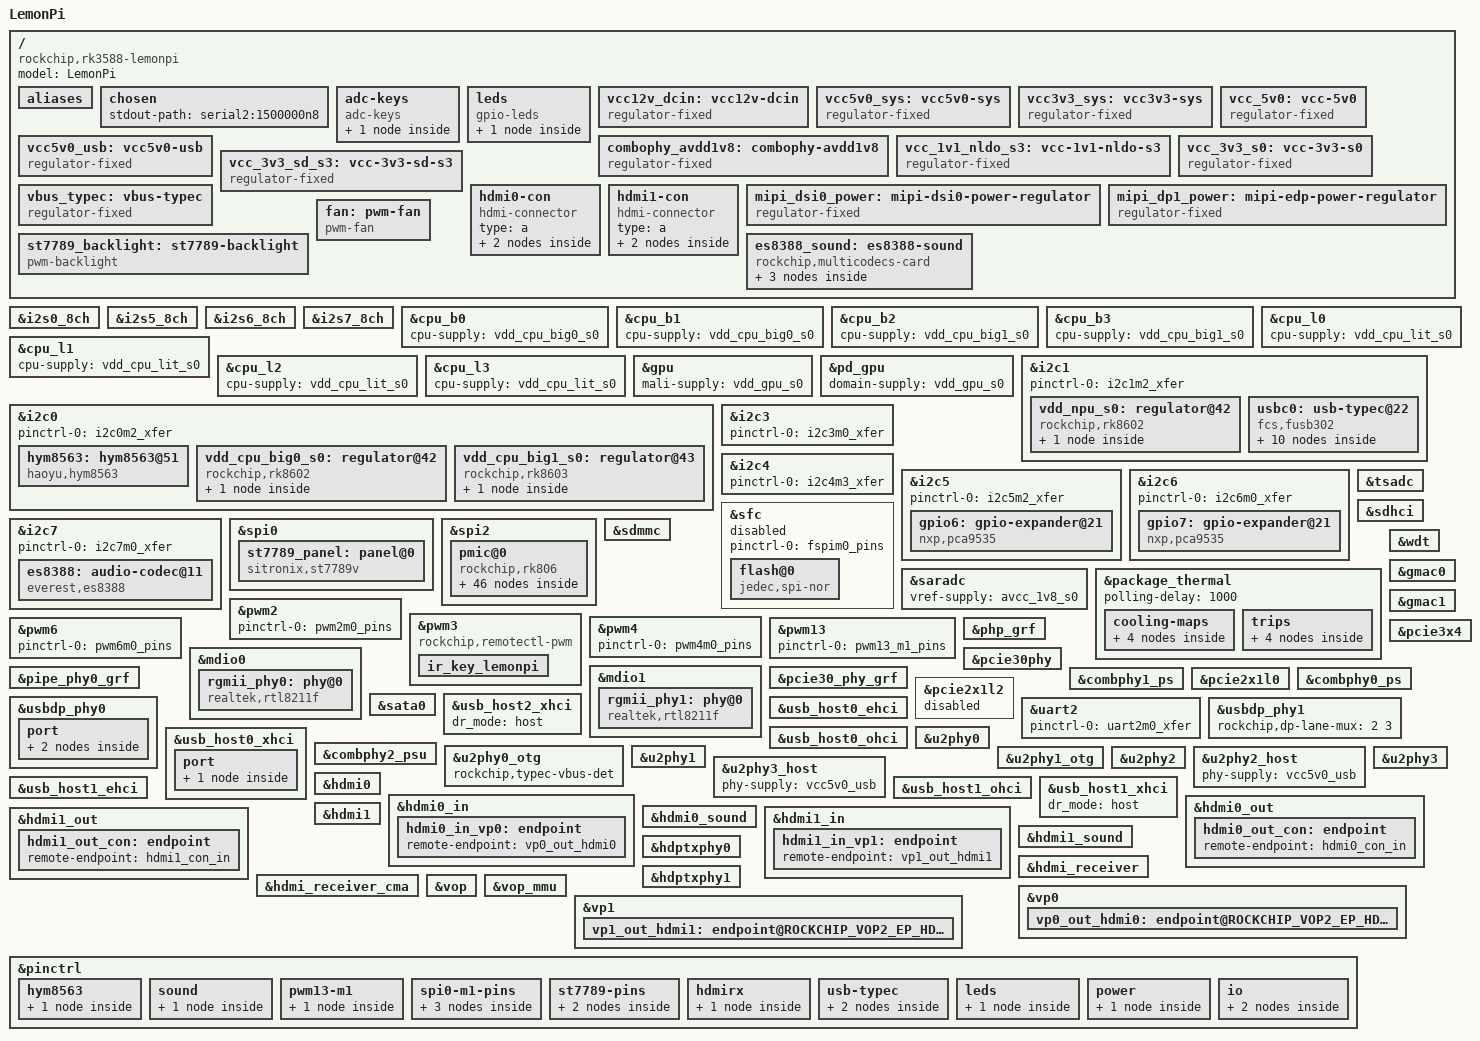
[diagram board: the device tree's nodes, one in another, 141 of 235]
// SPDX-License-Identifier: (GPL-2.0+ OR MIT)
/*
 * Copyright (c) 2021 Rockchip Electronics Co., Ltd.
 * Device Tree Source for LemonPi board on Rockchip RK3588 SoC.
 *
 */

/dts-v1/;
#include <dt-bindings/gpio/gpio.h>
#include <dt-bindings/input/input.h>
#include <dt-bindings/pinctrl/rockchip.h>
#include <dt-bindings/soc/rockchip,vop2.h>
#include <dt-bindings/usb/pd.h>
#include "rk3588.dtsi"

/ {
	model = "LemonPi";
	compatible = "rockchip,rk3588-lemonpi", "rockchip,rk3588";

	/* Device aliases for system devices */
	aliases {
		mmc0 = &sdhci;
		mmc1 = &sdmmc;
		ethernet0 = &gmac0;
		ethernet1 = &gmac1;
	};

	/* Kernel boot console output configuration */
	chosen {
		stdout-path = "serial2:1500000n8";
	};

	/* ADC keys for user buttons */
	adc-keys {
		compatible = "adc-keys";
		io-channels = <&saradc 1>;
		io-channel-names = "buttons";
		keyup-threshold-microvolt = <1800000>;
		poll-interval = <100>;
		status = "okay"; 
		
		power {
			label = "power";
			linux,code = <KEY_POWER>;
			press-threshold-microvolt = <1750>;
		};
	};

	/* On-board status LEDs */
	leds: leds {
		status = "okay";
		compatible = "gpio-leds";

		sys_led: sys-led {
			label = "sys_led";
			linux,default-trigger = "heartbeat";
			default-state = "on";
			gpios = <&gpio0 RK_PD3 GPIO_ACTIVE_LOW>;
			pinctrl-names = "default";
			pinctrl-0 = <&sys_led_pins>;
		};
	};

	/* 12V DC input power supply */
	vcc12v_dcin: vcc12v-dcin {
		compatible = "regulator-fixed";
		regulator-always-on;
		regulator-boot-on;
		regulator-min-microvolt = <12000000>;
		regulator-max-microvolt = <12000000>;
		regulator-name = "vcc12v_dcin";
	};

	/* 5V system power supply */
	vcc5v0_sys: vcc5v0-sys {
		compatible = "regulator-fixed";
		regulator-name = "vcc5v0_sys";
		regulator-always-on;
		regulator-boot-on;
		regulator-min-microvolt = <5000000>;
		regulator-max-microvolt = <5000000>;
		vin-supply = <&vcc12v_dcin>;
	};

	/* 3.3V system power supply */
	vcc3v3_sys: vcc3v3-sys {
		compatible = "regulator-fixed";
		regulator-name = "vcc3v3_sys";
		regulator-always-on;
		regulator-boot-on;
		regulator-min-microvolt = <3300000>;
		regulator-max-microvolt = <3300000>;
		vin-supply = <&vcc12v_dcin>;
	};

	/* 5V peripheral power supply */
	vcc_5v0: vcc-5v0 {
		compatible = "regulator-fixed";
		regulator-name = "vcc_5v0";
		regulator-always-on;
		regulator-boot-on;
		regulator-min-microvolt = <5000000>;
		regulator-max-microvolt = <5000000>;
		vin-supply = <&vcc5v0_sys>;
		enable-active-high;
		gpio = <&gpio4 RK_PA3 GPIO_ACTIVE_HIGH>;
		pinctrl-names = "default";
		pinctrl-0 = <&vcc_5v0_en>;
	};

	/* 5V USB power supply */
	vcc5v0_usb: vcc5v0-usb {
		compatible = "regulator-fixed";
		regulator-name = "vcc5v0_usb";
		regulator-always-on;
		regulator-boot-on;
		regulator-min-microvolt = <5000000>;
		regulator-max-microvolt = <5000000>;
		vin-supply = <&vcc5v0_sys>;
	};
	
	/* 1.8V Combo PHY analog power supply */
	combophy_avdd1v8: combophy-avdd1v8 {
		compatible = "regulator-fixed";
		regulator-name = "combophy_avdd1v8";
		regulator-boot-on;
		regulator-min-microvolt = <1800000>;
		regulator-max-microvolt = <1800000>;
		vin-supply = <&avcc_1v8_s0>;
	};

	/* 1.1V NLDO S3 power supply */
	vcc_1v1_nldo_s3: vcc-1v1-nldo-s3 {
		compatible = "regulator-fixed";
		regulator-name = "vcc_1v1_nldo_s3";
		regulator-always-on;
		regulator-boot-on;
		regulator-min-microvolt = <1100000>;
		regulator-max-microvolt = <1100000>;
		vin-supply = <&vcc5v0_sys>;
	};

	/* 3.3V S0 power supply */
	vcc_3v3_s0: vcc-3v3-s0 {
		compatible = "regulator-fixed";
		regulator-name = "vcc_3v3_s0";
		regulator-always-on;
		regulator-boot-on;
		regulator-min-microvolt = <3300000>;
		regulator-max-microvolt = <3300000>;
		vin-supply = <&vcc_3v3_s3>;
	};

	/* 3.3V SD S3 power supply */
	vcc_3v3_sd_s3: vcc-3v3-sd-s3 {
		compatible = "regulator-fixed";
		regulator-name = "vcc_3v3_sd_s3";
		regulator-always-on;
		regulator-boot-on;
		regulator-min-microvolt = <3300000>;
		regulator-max-microvolt = <3300000>;
		vin-supply = <&vcc_3v3_s3>;
	};

	/* Type-C VBUS power supply */
	vbus_typec: vbus-typec {
		compatible = "regulator-fixed";
		enable-active-high;
		gpio = <&gpio2 RK_PB5 GPIO_ACTIVE_HIGH>;
		pinctrl-names = "default";
		pinctrl-0 = <&typec_pwren>;
		regulator-name = "vbus_typec";
		regulator-min-microvolt = <5000000>;
		regulator-max-microvolt = <5000000>;
		regulator-always-on;
		regulator-boot-on;
		vin-supply = <&vcc5v0_usb>;
	};

	/* HDMI0 connector */
	hdmi0-con {
		compatible = "hdmi-connector";
		type = "a";

		port {
			hdmi0_con_in: endpoint {
				remote-endpoint = <&hdmi0_out_con>;
			};
		};
	};

	/* HDMI1 connector */
	hdmi1-con {
		compatible = "hdmi-connector";
		type = "a";
		port {
			hdmi1_con_in: endpoint {
				remote-endpoint = <&hdmi1_out_con>;
			};
		};
	};
	
	/* MIPI DSI0 power supply */
	mipi_dsi0_power: mipi-dsi0-power-regulator {
		compatible = "regulator-fixed";
		regulator-name = "mipi_dsi0_power";
		gpio = <&gpio1 RK_PD2 GPIO_ACTIVE_HIGH>;
		enable-active-high;
		regulator-boot-on;
		regulator-always-on;
	};

	/* MIPI eDP power supply */
	mipi_dp1_power: mipi-edp-power-regulator {
		compatible = "regulator-fixed";
		regulator-name = "mipi_dp1_power";
		gpio = <&gpio0 RK_PA0 GPIO_ACTIVE_HIGH>;
		enable-active-high;
		regulator-boot-on;
		regulator-always-on;
	};

	/* BEGIN: ST7789 Backlight Node */
	st7789_backlight: st7789-backlight { 
		compatible = "pwm-backlight";
		pwms = <&pwm13 0 100000 0>; 
		brightness-levels = <0 4 8 16 32 64 128 255>;
		default-brightness-level = <6>;
		power-supply = <&vcc3v3_sys>;
		status = "okay";
	};

	/* Audio codec and analog audio card (ES8388) */
	es8388_sound: es8388-sound {
		status = "okay";
		compatible = "rockchip,multicodecs-card";
		rockchip,card-name = "rockchip-es8388";
		hp-det-gpio = <&gpio1 RK_PD3 GPIO_ACTIVE_HIGH>;
		hp-con-gpio = <&gpio1 RK_PB5 GPIO_ACTIVE_HIGH>;
		io-channels = <&saradc 4>;
		io-channel-names = "adc-detect";
		keyup-threshold-microvolt = <1800000>;
		poll-interval = <100>;
		rockchip,format = "i2s";
		rockchip,mclk-fs = <256>;
		rockchip,cpu = <&i2s0_8ch>;
		rockchip,codec = <&es8388>;
		rockchip,audio-routing =
			"Headphone", "LOUT1",
			"Headphone", "ROUT1",
			"Headphone", "Headphone Power",
			"Headphone", "Headphone Power",
			"LINPUT1", "Main Mic",
			"LINPUT2", "Main Mic",
			"RINPUT1", "Headset Mic",
			"RINPUT2", "Headset Mic";
		pinctrl-names = "default";
		pinctrl-0 = <&hp_detect>;
		play-pause-key {
			label = "playpause";
			linux,code = <KEY_PLAYPAUSE>;
			press-threshold-microvolt = <2000>;
		};

		previous-song-key {
			label = "previoussong";
			linux,code = <KEY_PREVIOUSSONG>;
			press-threshold-microvolt = <145000>;
		};

		next-song-key {
			label = "nextsong";
			linux,code = <KEY_NEXTSONG>;
			press-threshold-microvolt = <290000>;
		};
	};

	/* PWM fan for system cooling */
	fan: pwm-fan {
		compatible = "pwm-fan";
		#cooling-cells = <2>;
		pwms = <&pwm4 0 50000 0>;
		cooling-levels = <0 25 100 150 255>;
	};
};

/* I2S0 8-channel audio interface */
&i2s0_8ch {
	status = "okay";
	rockchip,clk-trcm = <0>;
	pinctrl-names = "default"; 
	pinctrl-0 = <&i2s0_lrck
		     &i2s0_mclk
		     &i2s0_sclk
		     &i2s0_sdi0
		     &i2s0_sdo0>;
};

/* I2S5 8-channel audio interface */
&i2s5_8ch {
	status = "okay";
};

/* I2S6 8-channel audio interface */
&i2s6_8ch {
	status = "okay";
};

/* I2S7 8-channel audio interface */
&i2s7_8ch{
	status = "okay";
};

/* CPU big cluster 0 power supply */
&cpu_b0 {
	cpu-supply = <&vdd_cpu_big0_s0>;
};

/* CPU big cluster 1 power supply */
&cpu_b1 {
	cpu-supply = <&vdd_cpu_big0_s0>;
};

/* CPU big cluster 2 power supply */
&cpu_b2 {
	cpu-supply = <&vdd_cpu_big1_s0>;
};

/* CPU big cluster 3 power supply */
&cpu_b3 {
	cpu-supply = <&vdd_cpu_big1_s0>;
};

/* CPU little cluster 0 power supply */
&cpu_l0 {
	cpu-supply = <&vdd_cpu_lit_s0>;
};

/* CPU little cluster 1 power supply */
&cpu_l1 {
	cpu-supply = <&vdd_cpu_lit_s0>;
};

/* CPU little cluster 2 power supply */
&cpu_l2 {
	cpu-supply = <&vdd_cpu_lit_s0>;
};

/* CPU little cluster 3 power supply */
&cpu_l3 {
	cpu-supply = <&vdd_cpu_lit_s0>;
};

/* GPU configuration */
&gpu {
	mali-supply = <&vdd_gpu_s0>;
	status = "okay";
};

/* GPU power domain configuration */
&pd_gpu {
	domain-supply = <&vdd_gpu_s0>;
};

/* I2C0 bus for RTC and regulators */
&i2c0 {
	pinctrl-names = "default";
	pinctrl-0 = <&i2c0m2_xfer>;
	status = "okay";

	hym8563: hym8563@51 {
		compatible = "haoyu,hym8563";
		reg = <0x51>;
		#clock-cells = <0>;
		clock-frequency = <32768>;
		clock-output-names = "hym8563";
		pinctrl-names = "default";
		pinctrl-0 = <&hym8563_int>;
		interrupt-parent = <&gpio0>;
		interrupts = <RK_PB0 IRQ_TYPE_LEVEL_LOW>;
		wakeup-source;
	};

	vdd_cpu_big0_s0: regulator@42 {
		compatible = "rockchip,rk8602";
		reg = <0x42>;
		fcs,suspend-voltage-selector = <1>;
		regulator-compatible = "rk860x-reg";
		regulator-name = "vdd_cpu_big0_s0";
		regulator-always-on;
		regulator-boot-on;
		regulator-min-microvolt = <550000>;
		regulator-max-microvolt = <1050000>;
		regulator-ramp-delay = <2300>;
		vin-supply = <&vcc5v0_sys>;

		regulator-state-mem {
			regulator-off-in-suspend;
		};
	};

	vdd_cpu_big1_s0: regulator@43 {
		compatible = "rockchip,rk8603", "rockchip,rk8602";
		reg = <0x43>;
		fcs,suspend-voltage-selector = <1>;
		regulator-compatible = "rk860x-reg";
		regulator-name = "vdd_cpu_big1_s0";
		regulator-always-on;
		regulator-boot-on;
		regulator-min-microvolt = <550000>;
		regulator-max-microvolt = <1050000>;
		regulator-ramp-delay = <2300>;
		vin-supply = <&vcc5v0_sys>;

		regulator-state-mem {
			regulator-off-in-suspend;
		};
	};
};

/* I2C1 bus for NPU regulator and Type-C controller */
&i2c1 {
	pinctrl-names = "default";
	pinctrl-0 = <&i2c1m2_xfer>;
	status = "okay";

	vdd_npu_s0: regulator@42 {
		compatible = "rockchip,rk8602";
		reg = <0x42>;
		vin-supply = <&vcc5v0_sys>;
		regulator-compatible = "rk860x-reg";
		regulator-name = "vdd_npu_s0";
		regulator-min-microvolt = <550000>;
		regulator-max-microvolt = <950000>;
		regulator-ramp-delay = <2300>;
		rockchip,suspend-voltage-selector = <1>;
		regulator-boot-on;
		regulator-always-on;

		regulator-state-mem {
			regulator-off-in-suspend;
		};
	};

	usbc0: usb-typec@22 {
		compatible = "fcs,fusb302";
		reg = <0x22>;
		interrupt-parent = <&gpio0>;
		interrupts = <RK_PC4 IRQ_TYPE_LEVEL_LOW>;
		pinctrl-names = "default";
		pinctrl-0 = <&usbc0_int>;
		vbus-supply = <&vbus_typec>;
		status = "okay";

		usb_con: connector {
			compatible = "usb-c-connector";
			label = "USB-C";
			data-role = "dual";
			power-role = "dual";
			try-power-role = "sink";
			op-sink-microwatt = <1000000>;
			sink-pdos = <PDO_FIXED(5000, 1000, PDO_FIXED_USB_COMM)>;
			source-pdos = <PDO_FIXED(5000, 3000, PDO_FIXED_USB_COMM)>;

			altmodes {
				#address-cells = <1>;
				#size-cells = <0>;

				altmode@0 {
					reg = <0>;
					svid = <0xff01>;
					vdo = <0xffffffff>;
				};
			};

			ports {
				#address-cells = <1>;
				#size-cells = <0>;

				port@0 {
					reg = <0>;
					usbc0_orien_sw: endpoint {
						remote-endpoint = <&usbdp_phy0_orientation_switch>;
					};
				};

				port@1 {
					reg = <1>;

					usbc0_role_sw: endpoint {
						remote-endpoint = <&dwc3_0_role_switch>;
					};
				};

				port@2 {
					reg = <2>;

					dp_altmode_mux: endpoint {
						remote-endpoint = <&usbdp_phy0_dp_altmode_mux>;
					};
				};
			};
		};
	};
};

/* I2C3 bus */
&i2c3 {
	status = "okay";
	pinctrl-names = "default";
	pinctrl-0 = <&i2c3m0_xfer>;
};

/* I2C4 bus */
&i2c4 {
	status = "okay";
	pinctrl-names = "default";
	pinctrl-0 = <&i2c4m3_xfer>;
};

/* I2C5 bus with GPIO expander */
&i2c5 {
	pinctrl-names = "default";
	pinctrl-0 = <&i2c5m2_xfer>;
	status = "okay";

	gpio6: gpio-expander@21 {
		compatible = "nxp,pca9535";
		vcc-supply = <&vcc_3v3_s0>;
		status = "okay";
		reg = <0x21>;
		gpio-controller;
		#gpio-cells = <2>;
	};
};

/* I2C6 bus with GPIO expander */
&i2c6 {
	status = "okay";
	pinctrl-names = "default";
	pinctrl-0 = <&i2c6m0_xfer>;

	gpio7: gpio-expander@21 {
		compatible = "nxp,pca9535";
		status = "okay";
		reg = <0x21>;
		gpio-controller;
		#gpio-cells = <2>;
	};
};

/* I2C7 bus for ES8388 Audio Codec */
&i2c7 { 
	pinctrl-names = "default";
	pinctrl-0 = <&i2c7m0_xfer>;
	status = "okay";

	es8388: audio-codec@11 {
		status = "okay";
		#sound-dai-cells = <0>;
		compatible = "everest,es8388", "everest,es8323";
		reg = <0x11>;
		clocks = <&cru I2S0_8CH_MCLKOUT>;
		clock-names = "mclk";
		assigned-clocks = <&cru I2S0_8CH_MCLKOUT>;
		assigned-clock-rates = <12288000>;
		/* 从 ES8388 节点中移除 MCLK 的 pinctrl 声明 */
		// pinctrl-names = "default";
		// pinctrl-0 = <&i2s0_mclk>;
		DVDD-supply = <&vcc_1v8_s0>;
		AVDD-supply = <&avcc_1v8_s0>;
		PVDD-supply = <&vcc_3v3_s0>;
		HPVDD-supply = <&vcc_3v3_s0>;
	};
};

&sfc {
	status = "disabled"; 
	pinctrl-names = "default";
	pinctrl-0 = <&fspim0_pins>;

	flash@0 {
		compatible = "jedec,spi-nor";
		reg = <0x0>;
		spi-max-frequency = <100000000>;
		spi-rx-bus-width = <4>; 
		spi-tx-bus-width = <1>;
	};
};

/* SPI0 bus for pwm13 */
&spi0 {
	pinctrl-names = "default";
	pinctrl-0 = <&spi0m1_clk_pins>, <&spi0m1_mosi_pins>,
				<&spi0m1_cs0_pins>;
	status = "okay";

	st7789_panel: panel@0 {
		compatible = "sitronix,st7789v";
		reg = <0>;
        spi-max-frequency = <48000000>;
		/* For SPI Mode 0 (CPOL=0, CPHA=0), no spi-cpol or spi-cpha flags needed */

		/*
		 * The pinctrl for DC and RESET pins (configured as GPIOs) is handled
		 * by the pinctrl definitions under &pinctrl { st7789_gpio_pins { ... } }.
		 * The panel driver will request these GPIOs using the dc-gpios and reset-gpios
		 * properties. The panel node itself typically does not need its own pinctrl-0
		 * if these are standard GPIO controls.
		 * So, the following line should be removed:
		 * pinctrl-names = "default";
		 * pinctrl-0 = <&st7789_dc_pins>, <&st7789_reset_pins>;
		 */

		pinctrl-names = "default";
		pinctrl-0 = <&st7789_dc_pins>, <&st7789_reset_pins>;
		reset-gpios = <&gpio4 RK_PB0 GPIO_ACTIVE_LOW>;
		dc-gpios = <&gpio4 RK_PA0 GPIO_ACTIVE_HIGH>;

		backlight = <&st7789_backlight>;

		width = <172>;
		height = <320>;
		rotate = <90>;
		fps = <30>;
		buswidth = <8>;
		status = "okay";
	};
};

/* SPI2 bus for PMIC */
&spi2 {
	status = "okay";
	assigned-clocks = <&cru CLK_SPI2>;
	assigned-clock-rates = <200000000>;
	pinctrl-names = "default";
	pinctrl-0 = <&spi2m2_cs0 &spi2m2_pins>;
	num-cs = <1>;

	pmic@0 {
		compatible = "rockchip,rk806";
		spi-max-frequency = <1000000>;
		reg = <0x0>;

		interrupt-parent = <&gpio0>;
		interrupts = <7 IRQ_TYPE_LEVEL_LOW>;

		pinctrl-names = "default";
		pinctrl-0 = <&pmic_pins>, <&rk806_dvs1_null>,
				<&rk806_dvs2_null>, <&rk806_dvs3_null>;
		system-power-controller;

		vcc1-supply = <&vcc5v0_sys>;
		vcc2-supply = <&vcc5v0_sys>;
		vcc3-supply = <&vcc5v0_sys>;
		vcc4-supply = <&vcc5v0_sys>;
		vcc5-supply = <&vcc5v0_sys>;
		vcc6-supply = <&vcc5v0_sys>;
		vcc7-supply = <&vcc5v0_sys>;
		vcc8-supply = <&vcc5v0_sys>;
		vcc9-supply = <&vcc5v0_sys>;
		vcc10-supply = <&vcc5v0_sys>;
		vcc11-supply = <&vcc_2v0_pldo_s3>;
		vcc12-supply = <&vcc5v0_sys>;
		vcc13-supply = <&vcc_1v1_nldo_s3>;
		vcc14-supply = <&vcc_1v1_nldo_s3>;
		vcca-supply = <&vcc5v0_sys>;

		gpio-controller;
		#gpio-cells = <2>;

		rk806_dvs1_null: dvs1-null-pins {
			pins = "gpio_pwrctrl1";
			function = "pin_fun0";
		};

		rk806_dvs2_null: dvs2-null-pins {
			pins = "gpio_pwrctrl2";
			function = "pin_fun0";
		};

		rk806_dvs3_null: dvs3-null-pins {
			pins = "gpio_pwrctrl3";
			function = "pin_fun0";
		};

		regulators {
			vdd_gpu_s0: dcdc-reg1 {
				regulator-always-on;
				regulator-boot-on;
				regulator-min-microvolt = <550000>;
				regulator-max-microvolt = <950000>;
				regulator-ramp-delay = <12500>;
				regulator-name = "vdd_gpu_s0";
				regulator-enable-ramp-delay = <400>;
				
				regulator-state-mem {
					regulator-off-in-suspend;
				};
			};

			vdd_cpu_lit_s0: dcdc-reg2 {
				regulator-name = "vdd_cpu_lit_s0";
				regulator-always-on;
				regulator-boot-on;
				regulator-min-microvolt = <550000>;
				regulator-max-microvolt = <950000>;
				regulator-ramp-delay = <12500>;

				regulator-state-mem {
					regulator-off-in-suspend;
				};
			};

			vdd_log_s0: dcdc-reg3 {
				regulator-always-on;
				regulator-boot-on;
				regulator-min-microvolt = <675000>;
				regulator-max-microvolt = <750000>;
				regulator-ramp-delay = <12500>;
				regulator-name = "vdd_log_s0";

				regulator-state-mem {
					regulator-off-in-suspend;
					regulator-suspend-microvolt = <750000>;
				};
			};

			vdd_vdenc_s0: dcdc-reg4 {
				regulator-name = "vdd_vdenc_s0";
				regulator-always-on;
				regulator-boot-on;
				regulator-min-microvolt = <550000>;
				regulator-max-microvolt = <950000>;
				regulator-init-microvolt = <750000>;
				regulator-ramp-delay = <12500>;

				regulator-state-mem {
					regulator-off-in-suspend;
				};
			};

			vdd_ddr_s0: dcdc-reg5 {
				regulator-name = "vdd_ddr_s0";
				regulator-always-on;
				regulator-boot-on;
				regulator-min-microvolt = <675000>;
				regulator-max-microvolt = <900000>;
				regulator-ramp-delay = <12500>;

				regulator-state-mem {
					regulator-off-in-suspend;
					regulator-suspend-microvolt = <850000>;
				};
			};

			vdd2_ddr_s3: dcdc-reg6 {
				regulator-always-on;
				regulator-boot-on;
				regulator-name = "vdd2_ddr_s3";
				
				regulator-state-mem {
					regulator-on-in-suspend;
				};
			};

			vcc_2v0_pldo_s3: dcdc-reg7 {
				regulator-always-on;
				regulator-boot-on;
				regulator-min-microvolt = <2000000>;
				regulator-max-microvolt = <2000000>;
				regulator-ramp-delay = <12500>;
				regulator-name = "vdd_2v0_pldo_s3";

				regulator-state-mem {
					regulator-on-in-suspend;
					regulator-suspend-microvolt = <2000000>;
				};
			};

			vcc_3v3_s3: dcdc-reg8 {
				regulator-always-on;
				regulator-boot-on;
				regulator-min-microvolt = <3300000>;
				regulator-max-microvolt = <3300000>;
				regulator-name = "vcc_3v3_s3";

				regulator-state-mem {
					regulator-on-in-suspend;
					regulator-suspend-microvolt = <3300000>;
				};
			};

			vddq_ddr_s0: dcdc-reg9 {
				regulator-always-on;
				regulator-boot-on;
				regulator-name = "vddq_ddr_s0";

				regulator-state-mem {
					regulator-off-in-suspend;
				};
			};

			vcc_1v8_s3: dcdc-reg10 {
				regulator-always-on;
				regulator-boot-on;
				regulator-min-microvolt = <1800000>;
				regulator-max-microvolt = <1800000>;
				regulator-name = "vcc_1v8_s3";

				regulator-state-mem {
					regulator-on-in-suspend;
					regulator-suspend-microvolt = <1800000>;
				};
			};

			avcc_1v8_s0: pldo-reg1 {
				regulator-always-on;
				regulator-boot-on;
				regulator-min-microvolt = <1800000>;
				regulator-max-microvolt = <1800000>;
				regulator-name = "avcc_1v8_s0";

				regulator-state-mem {
					regulator-off-in-suspend;
				};
			};

			vcc_1v8_s0: pldo-reg2 {
				regulator-always-on;
				regulator-boot-on;
				regulator-min-microvolt = <1800000>;
				regulator-max-microvolt = <1800000>;
				regulator-name = "vcc_1v8_s0";

				regulator-state-mem {
					regulator-off-in-suspend;
					regulator-suspend-microvolt = <1800000>;
				};
			};

			avdd_1v2_s0: pldo-reg3 {
				regulator-always-on;
				regulator-boot-on;
				regulator-min-microvolt = <1200000>;
				regulator-max-microvolt = <1200000>;
				regulator-name = "avdd_1v2_s0";

				regulator-state-mem {
					regulator-off-in-suspend;
				};
			};

			avcc_3v3_s0: pldo-reg4 {
				regulator-always-on;
				regulator-boot-on;
				regulator-min-microvolt = <3300000>;
				regulator-max-microvolt = <3300000>;
				regulator-name = "avcc_3v3_s0";
				
				regulator-state-mem {
					regulator-off-in-suspend;
				};
			};

			vccio_sd_s0: pldo-reg5 {
				regulator-always-on;
				regulator-boot-on;
				regulator-min-microvolt = <1800000>;
				regulator-max-microvolt = <3300000>;
				regulator-ramp-delay = <12500>;
				regulator-name = "vccio_sd_s0";

				regulator-state-mem {
					regulator-off-in-suspend;
				};
			};

			pldo6_s3: pldo-reg6 {
				regulator-always-on;
				regulator-boot-on;
				regulator-min-microvolt = <1800000>;
				regulator-max-microvolt = <1800000>;
				regulator-name = "pldo6_s3";

				regulator-state-mem {
					regulator-on-in-suspend;
					regulator-suspend-microvolt = <1800000>;
				};
			};

			vdd_0v75_s3: nldo-reg1 {
				regulator-always-on;
				regulator-boot-on;
				regulator-min-microvolt = <750000>;
				regulator-max-microvolt = <750000>;
				regulator-name = "vdd_0v75_s3";

				regulator-state-mem {
					regulator-on-in-suspend;
					regulator-suspend-microvolt = <750000>;
				};
			};

			vdd_ddr_pll_s0: nldo-reg2 {
				regulator-always-on;
				regulator-boot-on;
				regulator-min-microvolt = <850000>;
				regulator-max-microvolt = <850000>;
				regulator-name = "vdd_ddr_pll_s0";

				regulator-state-mem {
					regulator-off-in-suspend;
					regulator-suspend-microvolt = <850000>;
				};
			};

			avdd_0v75_s0: nldo-reg3 {
				regulator-always-on;
				regulator-boot-on;
				regulator-min-microvolt = <750000>;
				regulator-max-microvolt = <750000>;
				regulator-name = "avdd_0v75_s0";

				regulator-state-mem {
					regulator-off-in-suspend;
				};
			};

			vdd_0v85_s0: nldo-reg4 {
				regulator-always-on;
				regulator-boot-on;
				regulator-min-microvolt = <850000>;
				regulator-max-microvolt = <850000>;
				regulator-name = "vdd_0v85_s0";

				regulator-state-mem {
					regulator-off-in-suspend;
				};
			};

			vdd_0v75_s0: nldo-reg5 {
				regulator-always-on;
				regulator-boot-on;
				regulator-min-microvolt = <750000>;
				regulator-max-microvolt = <750000>;
				regulator-name = "vdd_0v75_s0";

				regulator-state-mem {
					regulator-off-in-suspend;
				};
			};
		};
	};
};

/* SARADC analog-to-digital converter */
&saradc {
	status = "okay";
	vref-supply = <&avcc_1v8_s0>;
};

/* TSADC thermal sensor */
&tsadc {
	status = "okay";
};

/* eMMC storage */
&sdhci {
	assigned-clock-rates = <200000000>, <24000000>, <200000000>;
	bus-width = <8>;
	max-frequency = <200000000>;
	mmc-hs200-1_8v;		
	non-removable;	
	pinctrl-names = "default";
	pinctrl-0 = <&emmc_bus8 &emmc_clk &emmc_cmd>;	
	supports-emmc;
	status = "okay";
};

/* microSD card slot */
&sdmmc {
	bus-width = <4>;
	cap-mmc-highspeed;
	cap-sd-highspeed;
	disable-wp;
	no-mmc;
	no-sdio;
	max-frequency = <50000000>;
	vmmc-supply = <&vcc_3v3_s3>;
	vqmmc-supply = <&vccio_sd_s0>;
	status = "okay";
};

/* Fan thermal zone and cooling maps */
&package_thermal {
	polling-delay = <1000>;

	cooling-maps {
		map0 {
			trip = <&package_fan0>;
			cooling-device = <&fan 1 1>;
		};

		map1 {
			trip = <&package_fan1>;
			cooling-device = <&fan 2 2>;
		};

		map3 {
			trip = <&package_fan2>;
			cooling-device = <&fan 3 3>;
		};

		map4 {
			trip = <&package_fan3>;
			cooling-device = <&fan 4 4>;
		};
	};

	trips {
		package_fan0: package-fan0 {
			temperature = <50000>;
			hysteresis = <5000>;
			type = "active";
		};

		package_fan1: package-fan1 {
			temperature = <55000>;
			hysteresis = <5000>;
			type = "active";
		};

		package_fan2: package-fan2 {
			temperature = <60000>;
			hysteresis = <5000>;
			type = "active";
		};

		package_fan3: package-fan3 {
			temperature = <65000>;
			hysteresis = <5000>;
			type = "active";
		};
	};
};

/* PWM2 controller */
&pwm2 {
	pinctrl-0 = <&pwm2m0_pins>;
	status = "okay";
};

/* PWM3 for IR receiver */
&pwm3 { 
	compatible = "rockchip,remotectl-pwm";
	pinctrl-names = "default";
	pinctrl-0 = <&pwm3m1_pins>;
	remote_pwm_id = <3>;
	handle_cpu_id = <1>;
	remote_support_psci = <0>;
	status = "okay";

	ir_key_lemonpi{
	rockchip,usercode = <0xff00>;
	rockchip,key_table =
		<0xba   KEY_POWER>,      /* 电源按键 */
		<0xb8   KEY_MENU>,       /* 菜单按键 */
		<0xbc   KEY_BACK>,       /* 返回按键 */
		<0xbb   KEY_HOME>,       /* home键按键 */
		<0xea   KEY_PLAY>,       /* 播放按键 */
		<0xbf   KEY_VOLUMEUP>,   /* 音量加按键 */
		<0xe6   KEY_VOLUMEDOWN>, /* 音量键按键 */
		<0xf6   KEY_FASTFORWARD>,/* 快进按键 */
		<0xf8   KEY_FASTREVERSE>,/* 快退按键 */
		<0xf2   KEY_BACKSPACE>,  /* BaskSpace按键 */
		<0xf3   KEY_1>,          /* 按键1 */
        <0xe7   KEY_2>,
        <0xa1   KEY_3>,
        <0xf7   KEY_4>,
        <0xe3   KEY_5>,
        <0xa5   KEY_6>,
        <0xbd   KEY_7>,
        <0xad   KEY_8>,
        <0xb5   KEY_9>,
		<0xe9   KEY_0>;          /* 按键0 */
	};
};

/* PWM4 controller */
&pwm4 {
	pinctrl-0 = <&pwm4m0_pins>;
	status = "okay";
};

/* PWM6 controller */
&pwm6 {
	pinctrl-0 = <&pwm6m0_pins>;
	status = "okay";
};

/* PWM13 controller */
&pwm13 {
    pinctrl-names = "default";
    pinctrl-0 = <&pwm13_m1_pins>; 
	status = "okay";
};

/* Watchdog timer */
&wdt {
	status = "okay";
};

/* GMAC0 Ethernet controller */
&gmac0 {
	/* Use rgmii-rxid mode to disable rx delay inside Soc */
	phy-mode = "rgmii-rxid";
	clock_in_out = "output";

	snps,reset-gpio = <&gpio4 RK_PC6 GPIO_ACTIVE_LOW>;
	snps,reset-active-low;
	/* Reset time is 20ms, 100ms for rtl8211f */
	snps,reset-delays-us = <0 20000 100000>;

	pinctrl-names = "default";
	pinctrl-0 = <&gmac0_miim
			 &gmac0_tx_bus2
			 &gmac0_rx_bus2
			 &gmac0_rgmii_clk
			 &gmac0_rgmii_bus>;

	tx_delay = <0x20>;
	/* rx_delay = <0x4f>; */

	phy-handle = <&rgmii_phy0>;
	status = "okay";
};

/* GMAC1 Ethernet controller */
&gmac1 {
	/* Use rgmii-rxid mode to disable rx delay inside Soc */
	phy-mode = "rgmii-rxid";
	clock_in_out = "output";

	snps,reset-gpio = <&gpio3 RK_PB7 GPIO_ACTIVE_LOW>;
	snps,reset-active-low;
	/* Reset time is 20ms, 100ms for rtl8211f */
	snps,reset-delays-us = <0 20000 100000>;

	pinctrl-names = "default";
	pinctrl-0 = <&gmac1_miim
			 &gmac1_tx_bus2
			 &gmac1_rx_bus2
			 &gmac1_rgmii_clk
			 &gmac1_rgmii_bus>;

	tx_delay = <0x20>;
	/* rx_delay = <0x4f>; */

	phy-handle = <&rgmii_phy1>;
	status = "okay";
};

/* MDIO0 bus for GMAC0 PHY */
&mdio0 {
	status = "okay";
	rgmii_phy0: phy@0 {
		compatible = "realtek,rtl8211f", "ethernet-phy-ieee802.3-c22";
		phy-supply = <&vcc3v3_sys>;
		reg = <0x00>;
	};
};

/* MDIO1 bus for GMAC1 PHY */
&mdio1 {
	status = "okay";
	rgmii_phy1: phy@0 {
		compatible = "realtek,rtl8211f", "ethernet-phy-ieee802.3-c22";
		phy-supply = <&vcc3v3_sys>;
		reg = <0x00>;
	};
};

&php_grf { 
    status = "okay";
};

&pipe_phy0_grf { 
    status = "okay";
};

/* PCIe3.0 PHY Port0 & Port1 */
&pcie30phy {
	status = "okay";
};

&pcie30_phy_grf {
	status = "okay";
};

/* PCIe3x4 M.2 M-Key slot */
&pcie3x4 {
	reset-gpios = <&gpio1 RK_PB2 GPIO_ACTIVE_HIGH>;
	vpcie3v3-supply = <&vcc3v3_sys>;
	num-lanes = <4>;
	status = "okay";
};

/* SATA30_HOST1/PCIe20x1_0 Combo PHY */
&combphy1_ps {
	status = "okay";
};

/* PCIe2x1l0 M.2 E-Key slot */
&pcie2x1l0 {
	reset-gpios = <&gpio4 RK_PA5 GPIO_ACTIVE_HIGH>;
	disable-gpios = <&gpio0 RK_PC6 GPIO_ACTIVE_HIGH>;
	status = "okay";
};

/* SATA30/PCIe20x1_2 Combo PHY */
&combphy0_ps {
	status = "okay";
};

/* PCIe2x1l2 slot */
&pcie2x1l2 {
	reset-gpios = <&gpio3 RK_PD1 GPIO_ACTIVE_HIGH>;
	disable-gpios = <&gpio3 RK_PC1 GPIO_ACTIVE_HIGH>;
	status = "disabled";
};

/* SATA-PCIe controller */
&sata0{
	ahci-supply = <&vcc_1v8_s0>;
	phy-supply = <&avcc_1v8_s0>; 
	status = "okay";
};

/* Debug UART2 */
&uart2 {
	pinctrl-0 = <&uart2m0_xfer>;
	status = "okay";
};

/* USB3 PHY for USB 3.0 Type-A port 1 */
&usbdp_phy1 {
	rockchip,dp-lane-mux = <2 3>;
	status = "okay";
};

/* USB 3.0 Type-A port 2 (lower) */
&usb_host2_xhci {
	status = "okay";
	dr_mode = "host";
};

/* USB3 PHY for USB Type-C port */
&usbdp_phy0 {
    orientation-switch;
    sbu1-dc-gpios = <&gpio1 RK_PA0 GPIO_ACTIVE_HIGH>;
    sbu2-dc-gpios = <&gpio1 RK_PA1 GPIO_ACTIVE_HIGH>;
    status = "okay";

    port {
        #address-cells = <1>;
        #size-cells = <0>;

		usbdp_phy0_orientation_switch: endpoint@0 {
            reg = <0>;
			remote-endpoint = <&usbc0_orien_sw>;
        };

		usbdp_phy0_dp_altmode_mux: endpoint@1 {
            reg = <1>;
			remote-endpoint = <&dp_altmode_mux>;
        };
    };
};

/* USB 2.0 Type-A port 0 */
&usb_host0_ehci {
	status = "okay";
};

/* USB 2.0 Type-A port 0 */
&usb_host0_ohci {
	status = "okay";
};

/* USB Type-C port 0 */
&usb_host0_xhci {
	dr_mode = "host";
	usb-role-switch;
	status = "okay";

	port {
		#address-cells = <1>;
		#size-cells = <0>;

		dwc3_0_role_switch: endpoint@0 {
			reg = <0>;
			remote-endpoint = <&usbc0_role_sw>;
		};
	};
};

/* Combo PHY 2 as USB3 PHY */
&combphy2_psu {
	status = "okay";
};

/* USB2 PHY for USB Type-C port */
&u2phy0 {
	status = "okay";
};

&u2phy0_otg {
	rockchip,typec-vbus-det;
	status = "okay";
};

/* USB2 PHY for USB 3.0 Type-A port 1 */
&u2phy1 {
	status = "okay";
};

&u2phy1_otg {
	status = "okay";
};

/* USB2 PHY for USB 2.0 Type-A port 2 */
&u2phy2 {
	status = "okay";
};

&u2phy2_host {
	phy-supply = <&vcc5v0_usb>;
	status = "okay";
};

/* USB2 PHY for USB 3.0 Type-A port 2 */
&u2phy3 {
	status = "okay";
};

&u2phy3_host {
	phy-supply = <&vcc5v0_usb>;
	status = "okay";
};

/* USB2.0 HOST1 Controller */
&usb_host1_ehci {
	status = "okay";
};

/* USB 3.0 Type-A port 2 (lower) */
&usb_host1_ohci {
	status = "okay";
};

/* USB 3.0 Type-A port 1 (upper) */
&usb_host1_xhci {
	dr_mode = "host";
	status = "okay";
};

/* HDMI0 controller */
&hdmi0 {
	status = "okay";
};

/* HDMI1 input endpoint */
&hdmi0_in {
	hdmi0_in_vp0: endpoint {
		remote-endpoint = <&vp0_out_hdmi0>;
	};
};

/* HDMI0 output endpoint */
&hdmi0_out {
	hdmi0_out_con: endpoint {
		remote-endpoint = <&hdmi0_con_in>;
	};
};

/* HDMI0 audio */
&hdmi0_sound {
	status = "okay";
};

/* HDMI1 controller */
&hdmi1 {
	status = "okay";
};

/* HDMI1 input endpoint */
&hdmi1_in {
	hdmi1_in_vp1: endpoint {
		remote-endpoint = <&vp1_out_hdmi1>;
	};
};

/* HDMI1 output endpoint */
&hdmi1_out {
	hdmi1_out_con: endpoint {
		remote-endpoint = <&hdmi1_con_in>;
	};
};

/* HDMI1 audio */
&hdmi1_sound {
	status = "okay";
};

/* HDMI receiver CMA memory */
&hdmi_receiver_cma {
	status = "okay";
};

/* HDMI receiver */
&hdmi_receiver {
	status = "okay";
	hpd-gpios = <&gpio1 RK_PD5 GPIO_ACTIVE_LOW>;
	pinctrl-0 = <&hdmim1_rx_cec &hdmim1_rx_hpdin &hdmim1_rx_scl &hdmim1_rx_sda &hdmirx_hpd>;
	pinctrl-names = "default";
	memory-region = <&hdmi_receiver_cma>;
};

/* HDMI PHY0 */
&hdptxphy0 {
	status = "okay";
};

/* HDMI PHY1 */
&hdptxphy1 {
	status = "okay";
};

/* Video Output Processor */
&vop {
	status = "okay";
};

/* VOP Memory Management Unit */
&vop_mmu {
	status = "okay";
};

/* VOP2 HDMI0 endpoint */
&vp0 {
	vp0_out_hdmi0: endpoint@ROCKCHIP_VOP2_EP_HDMI0 {
		reg = <ROCKCHIP_VOP2_EP_HDMI0>;
		remote-endpoint = <&hdmi0_in_vp0>;
	};
};

/* VOP2 HDMI1 endpoint */
&vp1 {
	vp1_out_hdmi1: endpoint@ROCKCHIP_VOP2_EP_HDMI1 {
		reg = <ROCKCHIP_VOP2_EP_HDMI1>;
		remote-endpoint = <&hdmi1_in_vp1>;
	};
};

/* Pin control configuration */
&pinctrl {
	hym8563 {
		hym8563_int: hym8563-int {
			rockchip,pins = <0 RK_PB0 RK_FUNC_GPIO &pcfg_pull_up>;
		};
	};

	sound {
		hp_detect: hp-detect {
			rockchip,pins = <1 RK_PD3 RK_FUNC_GPIO &pcfg_pull_none>;
		};
	};

	/* PWM13 M1 Pin Configuration (for J27 connector - Backlight) */
	pwm13-m1 {
		pwm13_m1_pins: pwm13-m1-pins {
			rockchip,pins = <4 RK_PB6 11 &pcfg_pull_none>;
		};
	};

	spi0-m1-pins  {
		spi0m1_clk_pins: spi0m1-clk-pins {
			rockchip,pins = <4 RK_PA2 8 &pcfg_pull_up_drv_level_1>;
		};
		spi0m1_mosi_pins: spi0m1-mosi-pins {
			rockchip,pins = <4 RK_PA1 8 &pcfg_pull_up_drv_level_1>;
		};
		spi0m1_cs0_pins: spi0m1-cs0-pin {
			rockchip,pins = <4 RK_PB2 8 &pcfg_pull_up_drv_level_1>; 
		};
	};

	st7789-pins {
		st7789_dc_pins: st7789-dc-pins {
			rockchip,pins = <4 RK_PA0 RK_FUNC_GPIO &pcfg_pull_none>;
		};

		st7789_reset_pins: st7789-reset-pins {
			rockchip,pins = <4 RK_PB0 RK_FUNC_GPIO &pcfg_pull_none>;
		};
	};
	
	hdmirx {
		hdmirx_hpd: hdmirx-hpd {
			rockchip,pins = <1 RK_PD5 RK_FUNC_GPIO &pcfg_pull_up>;
		};
	};

	usb-typec {
		usbc0_int: usbc0-int {
			rockchip,pins = <0 RK_PC4 RK_FUNC_GPIO &pcfg_pull_up>;
		};

		typec_pwren: typec-pwren {
			rockchip,pins = <2 RK_PB5 RK_FUNC_GPIO &pcfg_pull_none>;
		};
	};

	leds {
		sys_led_pins: sys-led-pins {
			rockchip,pins = <0 RK_PD3 RK_FUNC_GPIO &pcfg_pull_none>;
		};
	};

	power {
		vcc_5v0_en: vcc-5v0-en {
			rockchip,pins = <4 RK_PA3 RK_FUNC_GPIO &pcfg_pull_none>;
		};
	};
	
	io {
		pinctrl_pca9535_1: pinctrl-pca9535-1 {
			rockchip,pins = <2 RK_PC4 RK_FUNC_GPIO &pcfg_pull_none>;
		};

		pinctrl_pca9535_2: pinctrl-pca9535-2 {
			rockchip,pins = <2 RK_PC5 RK_FUNC_GPIO &pcfg_pull_none>;
		};
	};
};
